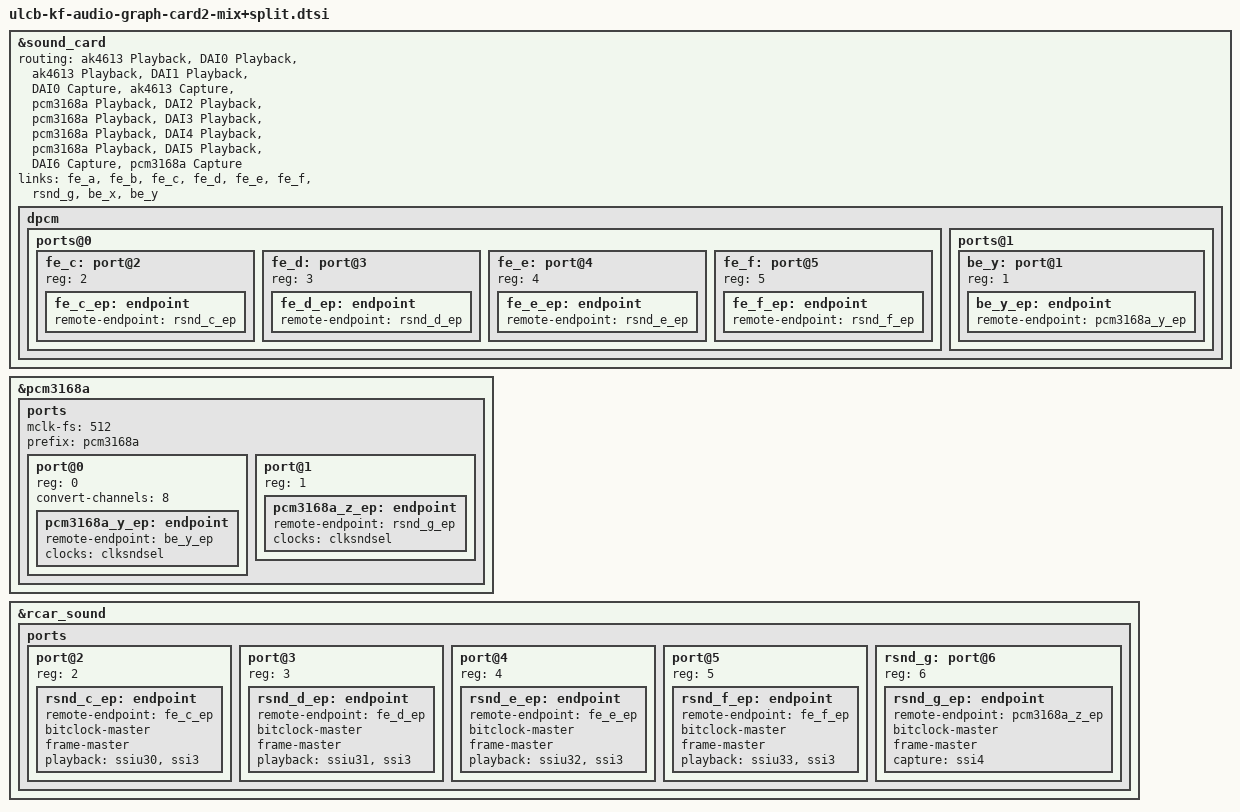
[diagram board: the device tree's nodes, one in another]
&sound_card {
	routing = "ak4613 Playback",   "DAI0 Playback",
		  "ak4613 Playback",   "DAI1 Playback",
		  "DAI0 Capture",      "ak4613 Capture",
		  "pcm3168a Playback", "DAI2 Playback",
		  "pcm3168a Playback", "DAI3 Playback",
		  "pcm3168a Playback", "DAI4 Playback",
		  "pcm3168a Playback", "DAI5 Playback",
		  "DAI6 Capture",      "pcm3168a Capture";
	/delete-property/ dais;
	links = <&fe_a		 
		 &fe_b		 
		 &fe_c		 
		 &fe_d		 
		 &fe_e		 
		 &fe_f		 
		 &rsnd_g	 
		 &be_x		 
		 &be_y		 
	>;
	dpcm {
		ports@0 {
		fe_c:	port@2 { reg = <2>; fe_c_ep: endpoint { remote-endpoint = <&rsnd_c_ep>; }; };
		fe_d:	port@3 { reg = <3>; fe_d_ep: endpoint { remote-endpoint = <&rsnd_d_ep>; }; };
		fe_e:	port@4 { reg = <4>; fe_e_ep: endpoint { remote-endpoint = <&rsnd_e_ep>; }; };
		fe_f:	port@5 { reg = <5>; fe_f_ep: endpoint { remote-endpoint = <&rsnd_f_ep>; }; };
		};
		ports@1 {
		be_y:	port@1 { reg = <1>; be_y_ep: endpoint { remote-endpoint = <&pcm3168a_y_ep>; }; };
		};
	};
};
&pcm3168a {
	ports {
		#address-cells = <1>;
		#size-cells = <0>;
		mclk-fs = <512>;
		prefix = "pcm3168a";
		port@0 {
			reg = <0>;
			convert-channels = <8>;  
			pcm3168a_y_ep: endpoint {
				remote-endpoint = <&be_y_ep>;
				clocks = <&clksndsel>;
			};
		};
		port@1 {
			reg = <1>;
			pcm3168a_z_ep: endpoint {
				remote-endpoint = <&rsnd_g_ep>;
				clocks = <&clksndsel>;
			};
		};
	};
};
&rcar_sound {
	ports {
		port@2 {
			reg = <2>;
			rsnd_c_ep: endpoint {
				remote-endpoint = <&fe_c_ep>;
				bitclock-master;
				frame-master;
				playback = <&ssiu30 &ssi3>;
			};
		};
		port@3 {
			reg = <3>;
			rsnd_d_ep: endpoint {
				remote-endpoint = <&fe_d_ep>;
				bitclock-master;
				frame-master;
				playback = <&ssiu31 &ssi3>;
			};
		};
		port@4 {
			reg = <4>;
			rsnd_e_ep: endpoint {
				remote-endpoint = <&fe_e_ep>;
				bitclock-master;
				frame-master;
				playback = <&ssiu32 &ssi3>;
			};
		};
		port@5 {
			reg = <5>;
			rsnd_f_ep: endpoint {
				remote-endpoint = <&fe_f_ep>;
				bitclock-master;
				frame-master;
				playback = <&ssiu33 &ssi3>;
			};
		};
		rsnd_g: port@6 {
			reg = <6>;
			rsnd_g_ep: endpoint {
				remote-endpoint = <&pcm3168a_z_ep>;
				bitclock-master;
				frame-master;
				capture = <&ssi4>;
			};
		};
	};
};
